# ddr32ss_EMIF_CTLCFG_0F308000h register map
Vendor: Texas Instruments
Registers are 32-bit, read-write, reset 0x0 unless marked. A register's access mark holds for its fields unless they carry their own. Offsets are as the file gives them; [hi:lo] are bit positions; {n}, {i} and the like mark numbered series.

## emif_ctlcfg (part 11 of 13)
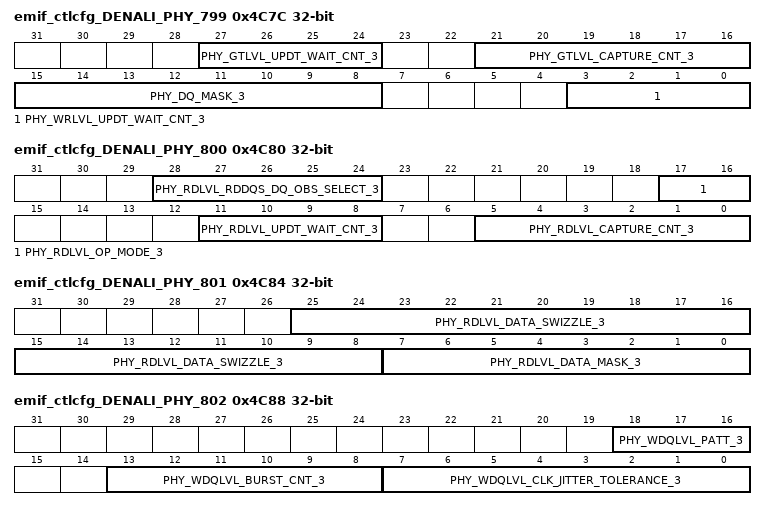
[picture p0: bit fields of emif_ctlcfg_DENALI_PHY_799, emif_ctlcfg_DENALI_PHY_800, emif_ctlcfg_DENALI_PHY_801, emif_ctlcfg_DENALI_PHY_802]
0x4C7C emif_ctlcfg_DENALI_PHY_799
  [27:24] PHY_GTLVL_UPDT_WAIT_CNT_3 — Number of cycles + 4 to wait after changing DQS target delay setting during gate training for slice 3. The valid range is 0x0 to 0xB. Reset Source: ctl_amod_g_rst_n
  [21:16] PHY_GTLVL_CAPTURE_CNT_3 — Number of samples to take at each DQS target delay setting during gate training for slice 3. Reset Source: ctl_amod_g_rst_n
  [15:8] PHY_DQ_MASK_3 — For ECC slice, should set this register to do DQ bit mask for slice 3. Reset Source: ctl_amod_g_rst_n
  [3:0] PHY_WRLVL_UPDT_WAIT_CNT_3 — Number of cycles to wait after changing DQS target delay setting during write leveling for slice 3. Reset Source: ctl_amod_g_rst_n
0x4C80 emif_ctlcfg_DENALI_PHY_800
  [28:24] PHY_RDLVL_RDDQS_DQ_OBS_SELECT_3 — Select value to map an individual DQ data window leading/trailing edge to the leading/trailing edge observation registers during read leveling for slice 3. Reset Source: ctl_amod_g_rst_n
  [17:16] PHY_RDLVL_OP_MODE_3 — Read leveling algorithm select for slice 3. Clear to 0 to move linearly from left to right. Set to 1 to start inside the window, move left and then move right. Reset Source: ctl_amod_g_rst_n
  [11:8] PHY_RDLVL_UPDT_WAIT_CNT_3 — Number of cycles to wait after changing DQS target delay setting during read leveling for slice 3. Reset Source: ctl_amod_g_rst_n
  [5:0] PHY_RDLVL_CAPTURE_CNT_3 — Number of samples to take at each DQS target delay setting during read leveling for slice 3. Reset Source: ctl_amod_g_rst_n
0x4C84 emif_ctlcfg_DENALI_PHY_801
  [25:8] PHY_RDLVL_DATA_SWIZZLE_3 — Read level bit swizzling for DDR4 operation for slice 3. Reset Source: ctl_amod_g_rst_n
  [7:0] PHY_RDLVL_DATA_MASK_3 — Per-bit mask for read leveling for slice 3. If all bits are not used, only 1 bit should be cleared to 0. Reset Source: ctl_amod_g_rst_n
0x4C88 emif_ctlcfg_DENALI_PHY_802
  [18:16] PHY_WDQLVL_PATT_3 — Defines the training patterns to be used during the write data leveling sequence for slice 3. Bit [0] corresponds to the LFSR data training pattern. Bit [1] corresponds to the CLK data training pattern. Bit [2] corresponds to user-defined data pattern training. If multiple bits are set, the training for each of the chosen patterns will be executed and the settings that give the smallest data valid window eye will be chosen. Reset Source: ctl_amod_g_rst_n
  [13:8] PHY_WDQLVL_BURST_CNT_3 — Defines the write/read burst length in bytes during the write data leveling sequence for slice 3. Reset Source: ctl_amod_g_rst_n
  [7:0] PHY_WDQLVL_CLK_JITTER_TOLERANCE_3 — Defines the minimum gap requirment for the LE and TE window for slice 3. Reset Source: ctl_amod_g_rst_n
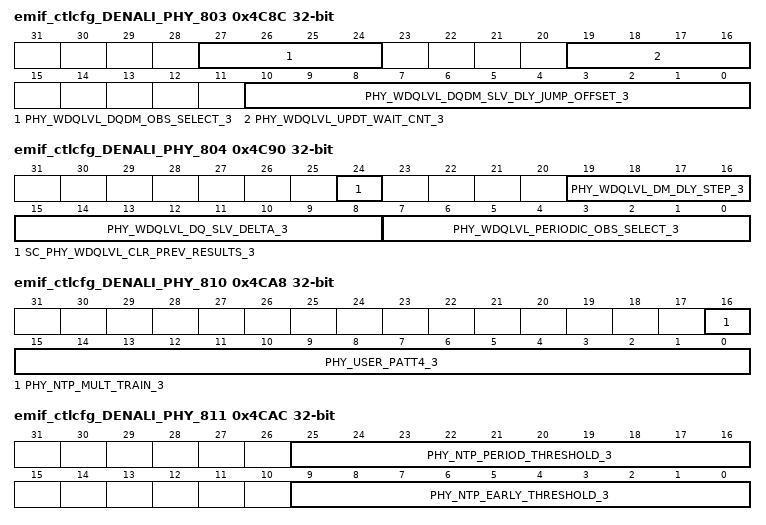
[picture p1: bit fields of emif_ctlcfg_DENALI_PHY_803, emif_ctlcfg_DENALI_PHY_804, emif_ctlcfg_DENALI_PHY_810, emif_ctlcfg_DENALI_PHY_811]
0x4C8C emif_ctlcfg_DENALI_PHY_803
  [27:24] PHY_WDQLVL_DQDM_OBS_SELECT_3 — Select value to map an individual DQ data window leading/trailing edge to the leading/trailing edge observation registers during write data leveling for slice 3. Reset Source: ctl_amod_g_rst_n
  [19:16] PHY_WDQLVL_UPDT_WAIT_CNT_3 — Number of cycles to wait after changing the DQ target delay setting during write data leveling for slice 3. Reset Source: ctl_amod_g_rst_n
  [10:0] PHY_WDQLVL_DQDM_SLV_DLY_JUMP_OFFSET_3 — Defines the target delay jump value when the TE window is found and begin to serch TE window for slice 3. Reset Source: ctl_amod_g_rst_n
0x4C90 emif_ctlcfg_DENALI_PHY_804 access per field
  [24] SC_PHY_WDQLVL_CLR_PREV_RESULTS_3 wo — Clears the previous result value to allow a clean slate comparison for future write DQ leveling results for slice 3. Set to 1 to trigger. WRITE-ONLY Reset Source: ctl_amod_g_rst_n
  [19:16] PHY_WDQLVL_DM_DLY_STEP_3 rw — The target delay line step for DM training for slice 3. Reset Source: ctl_amod_g_rst_n
  [15:8] PHY_WDQLVL_DQ_SLV_DELTA_3 rw — The margin for DQ0-7's LE and TE dealy to make sure the DQ bits can work during DM training for slice 3. Reset Source: ctl_amod_g_rst_n
  [7:0] PHY_WDQLVL_PERIODIC_OBS_SELECT_3 rw — Select value to map specific information during or post periodic write data leveling for slice 3. Reset Source: ctl_amod_g_rst_n
0x4C94 emif_ctlcfg_DENALI_PHY_805
  [8:0] PHY_WDQLVL_DATADM_MASK_3 — Per-bit mask for write data leveling for slice 3. Set to 1 to mask any bit from the leveling process. Reset Source: ctl_amod_g_rst_n
{0x4000+4i} emif_ctlcfg_DENALI_PHY_{i} (i=806..809)
  [31:0] PHY_USER_PATT{i-806}_3 — User-defined pattern to be used during write data leveling for slice 3. This register holds the bytes {4i-3221} to {4i-3224} written/read from device. Reset Source: ctl_amod_g_rst_n
0x4CA8 emif_ctlcfg_DENALI_PHY_810
  [16] PHY_NTP_MULT_TRAIN_3 — Control for single pass only No-Topology training for slice 3. Reset Source: ctl_amod_g_rst_n
  [15:0] PHY_USER_PATT4_3 — User-defined pattern to be used during write data leveling for slice 3. This register holds the DM bit for the 15 to 0 DQ written/read from device. Reset Source: ctl_amod_g_rst_n
0x4CAC emif_ctlcfg_DENALI_PHY_811
  [25:16] PHY_NTP_PERIOD_THRESHOLD_3 — Threshold Criteria of period threshold after No-Topology training is completed for slice 3. Reset Source: ctl_amod_g_rst_n
  [9:0] PHY_NTP_EARLY_THRESHOLD_3 — Threshold Criteria of early threshold after No-Topology training is completed for slice 3. Reset Source: ctl_amod_g_rst_n
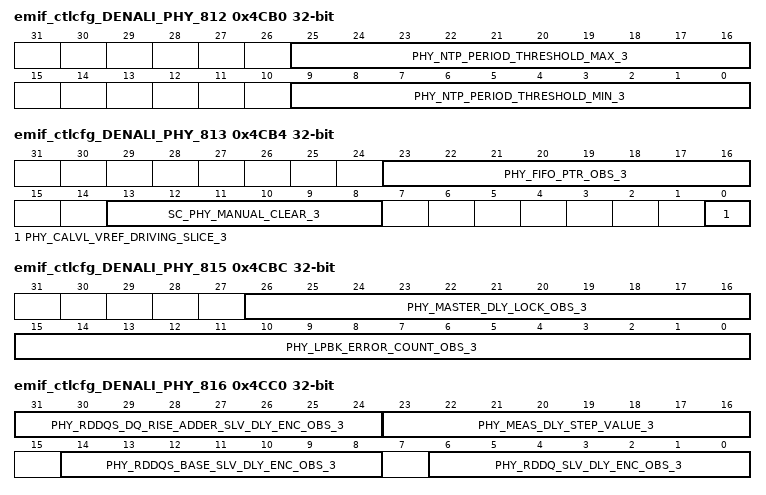
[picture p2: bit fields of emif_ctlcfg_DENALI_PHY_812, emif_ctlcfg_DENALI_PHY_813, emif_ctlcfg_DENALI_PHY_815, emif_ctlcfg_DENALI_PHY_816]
0x4CB0 emif_ctlcfg_DENALI_PHY_812
  [25:16] PHY_NTP_PERIOD_THRESHOLD_MAX_3 — Maximum Threshold that phy_clk_wrdqs_target_delay could cross boundary, to set period threshold/early threshold after No-Topology training is completed for slice 3. Reset Source: ctl_amod_g_rst_n
  [9:0] PHY_NTP_PERIOD_THRESHOLD_MIN_3 — Minimum Threshold that phy_clk_wrdqs_target_delay could cross boundary, to set period threshold/early threshold after No-Topology training is completed for slice 3. Reset Source: ctl_amod_g_rst_n
0x4CB4 emif_ctlcfg_DENALI_PHY_813 access per field
  [23:16] PHY_FIFO_PTR_OBS_3 ro — Observation register containing read entry FIFO pointers for slice 3. READ-ONLY Reset Source: ctl_amod_g_rst_n
  [13:8] SC_PHY_MANUAL_CLEAR_3 wo — Manual reset/clear of internal logic for slice 3. Bit [0] initiates manual setup of the read DQS gate. Bit [1] is reset of read entry FIFO pointers. Bit [2] is reset of master delay min/max lock values. Bit [3] is manual reset of master delay unlock counter. Bit [4] is reset of leveling error bit in the leveling status registers. Bit [5] is clearing of the gate tracking observation register. Set each bit to 1 to initiate/reset. WRITE-ONLY Reset Source: ctl_amod_g_rst_n
  [0] PHY_CALVL_VREF_DRIVING_SLICE_3 rw — Indicates if slice 3 is used to drive the VREF value to the device during CA training. Reset Source: ctl_amod_g_rst_n
0x4CB8 emif_ctlcfg_DENALI_PHY_814 ro reset 0x100000
  [31:0] PHY_LPBK_RESULT_OBS_3 — Observation register containing loopback status/results for slice 3. READ-ONLY Reset Source: ctl_amod_g_rst_n
0x4CBC emif_ctlcfg_DENALI_PHY_815 ro
  [26:16] PHY_MASTER_DLY_LOCK_OBS_3 — Observation register containing master delay results for slice 3. READ-ONLY Reset Source: ctl_amod_g_rst_n
  [15:0] PHY_LPBK_ERROR_COUNT_OBS_3 — Observation register containing total number of loopback error data for slice 3. READ-ONLY Reset Source: ctl_amod_g_rst_n
0x4CC0 emif_ctlcfg_DENALI_PHY_816 ro
  [31:24] PHY_RDDQS_DQ_RISE_ADDER_SLV_DLY_ENC_OBS_3 — Observation register containing read DQS DQ rising edge adder target delay encoded value for slice 3. READ-ONLY Reset Source: ctl_amod_g_rst_n
  [23:16] PHY_MEAS_DLY_STEP_VALUE_3 — Observation register containing fraction of the cycle in 1 delay element, numerator with demominator of 512, for slice 3. READ-ONLY Reset Source: ctl_amod_g_rst_n
  [14:8] PHY_RDDQS_BASE_SLV_DLY_ENC_OBS_3 — Observation register containing read DQS base target delay encoded value for slice 3. READ-ONLY Reset Source: ctl_amod_g_rst_n
  [6:0] PHY_RDDQ_SLV_DLY_ENC_OBS_3 — Observation register containing read DQ target delay encoded values for slice 3. READ-ONLY Reset Source: ctl_amod_g_rst_n
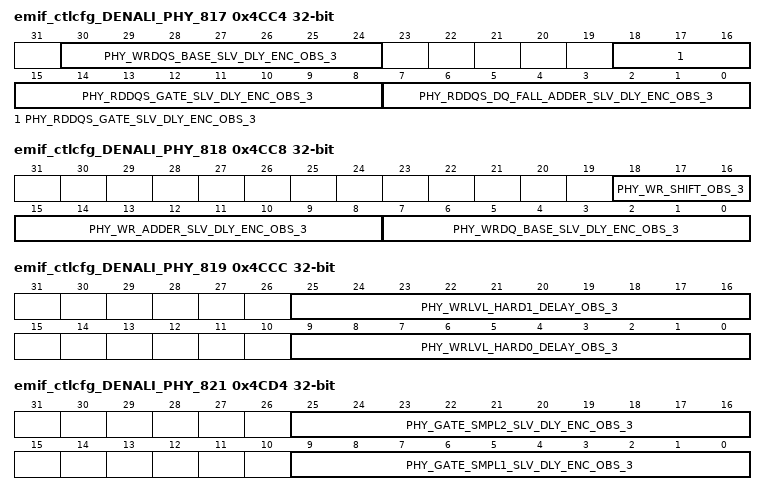
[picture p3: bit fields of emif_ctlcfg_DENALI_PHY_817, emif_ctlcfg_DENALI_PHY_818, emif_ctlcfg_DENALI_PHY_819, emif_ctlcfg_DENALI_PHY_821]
0x4CC4 emif_ctlcfg_DENALI_PHY_817 ro
  [30:24] PHY_WRDQS_BASE_SLV_DLY_ENC_OBS_3 — Observation register containing write DQS base target delay encoded value for slice 3. READ-ONLY Reset Source: ctl_amod_g_rst_n
  [18:8] PHY_RDDQS_GATE_SLV_DLY_ENC_OBS_3 — Observation register containing read DQS gate target delay encoded value for slice 3. READ-ONLY Reset Source: ctl_amod_g_rst_n
  [7:0] PHY_RDDQS_DQ_FALL_ADDER_SLV_DLY_ENC_OBS_3 — Observation register containing read DQS DQ falling edge adder target delay encoded value for slice 3. READ-ONLY Reset Source: ctl_amod_g_rst_n
0x4CC8 emif_ctlcfg_DENALI_PHY_818 ro
  [18:16] PHY_WR_SHIFT_OBS_3 — Observation register containing automatic half cycle and cycle shift values for slice 3. READ-ONLY Reset Source: ctl_amod_g_rst_n
  [15:8] PHY_WR_ADDER_SLV_DLY_ENC_OBS_3 — Observation register containing write adder target delay encoded value for slice 3. READ-ONLY Reset Source: ctl_amod_g_rst_n
  [7:0] PHY_WRDQ_BASE_SLV_DLY_ENC_OBS_3 — Observation register containing write DQ base target delay encoded value for slice 3. READ-ONLY Reset Source: ctl_amod_g_rst_n
0x4CCC emif_ctlcfg_DENALI_PHY_819 ro
  [25:16] PHY_WRLVL_HARD1_DELAY_OBS_3 — Observation register containing write leveling first hard 1 DQS target delay for slice 3. READ-ONLY Reset Source: ctl_amod_g_rst_n
  [9:0] PHY_WRLVL_HARD0_DELAY_OBS_3 — Observation register containing write leveling last hard 0 DQS target delay for slice 3. READ-ONLY Reset Source: ctl_amod_g_rst_n
0x4CD0 emif_ctlcfg_DENALI_PHY_820 ro
  [20:0] PHY_WRLVL_STATUS_OBS_3 — Observation register containing write leveling status for slice 3. READ-ONLY Reset Source: ctl_amod_g_rst_n
0x4CD4 emif_ctlcfg_DENALI_PHY_821 ro
  [25:16] PHY_GATE_SMPL2_SLV_DLY_ENC_OBS_3 — Observation register containing gate sample2 target delay encoded values for slice 3. READ-ONLY Reset Source: ctl_amod_g_rst_n
  [9:0] PHY_GATE_SMPL1_SLV_DLY_ENC_OBS_3 — Observation register containing gate sample1 target delay encoded values for slice 3. READ-ONLY Reset Source: ctl_amod_g_rst_n
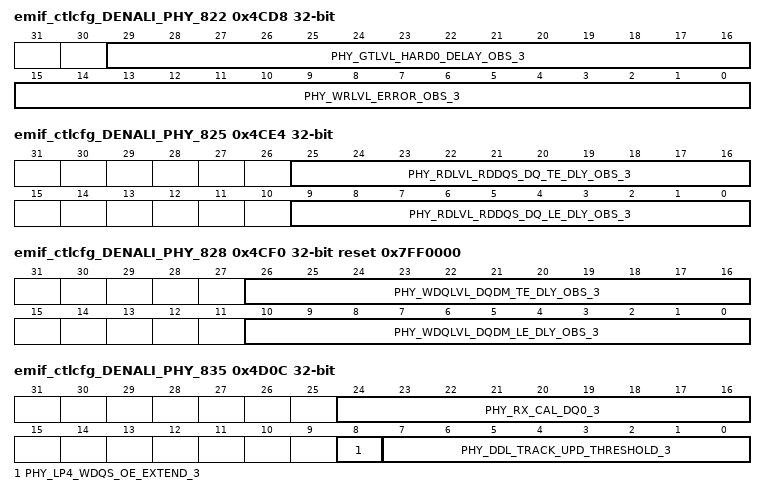
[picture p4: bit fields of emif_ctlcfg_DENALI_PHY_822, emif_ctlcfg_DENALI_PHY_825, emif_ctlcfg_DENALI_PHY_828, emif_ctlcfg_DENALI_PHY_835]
0x4CD8 emif_ctlcfg_DENALI_PHY_822 ro
  [29:16] PHY_GTLVL_HARD0_DELAY_OBS_3 — Observation register containing gate training first hard 0 DQS target delay for slice 3. READ-ONLY Reset Source: ctl_amod_g_rst_n
  [15:0] PHY_WRLVL_ERROR_OBS_3 — Observation register containing write leveling error status for slice 3. READ-ONLY Reset Source: ctl_amod_g_rst_n
0x4CDC emif_ctlcfg_DENALI_PHY_823 ro
  [13:0] PHY_GTLVL_HARD1_DELAY_OBS_3 — Observation register containing gate training last hard 1 DQS target delay for slice 3. READ-ONLY Reset Source: ctl_amod_g_rst_n
0x4CE0 emif_ctlcfg_DENALI_PHY_824 ro
  [17:0] PHY_GTLVL_STATUS_OBS_3 — Observation register containing gate training status for slice 3. READ-ONLY Reset Source: ctl_amod_g_rst_n
0x4CE4 emif_ctlcfg_DENALI_PHY_825 ro
  [25:16] PHY_RDLVL_RDDQS_DQ_TE_DLY_OBS_3 — Observation register containing read leveling data window trailing edge target delay setting for slice 3. READ-ONLY Reset Source: ctl_amod_g_rst_n
  [9:0] PHY_RDLVL_RDDQS_DQ_LE_DLY_OBS_3 — Observation register containing read leveling data window leading edge target delay setting for slice 3. READ-ONLY Reset Source: ctl_amod_g_rst_n
0x4CE8 emif_ctlcfg_DENALI_PHY_826 ro
  [1:0] PHY_RDLVL_RDDQS_DQ_NUM_WINDOWS_OBS_3 — Observation register containing read leveling number of windows found for slice 3. READ-ONLY Reset Source: ctl_amod_g_rst_n
0x4CEC emif_ctlcfg_DENALI_PHY_827 ro
  [31:0] PHY_RDLVL_STATUS_OBS_3 — Observation register containing read leveling status for slice 3. READ-ONLY Reset Source: ctl_amod_g_rst_n
0x4CF0 emif_ctlcfg_DENALI_PHY_828 ro reset 0x7FF0000
  [26:16] PHY_WDQLVL_DQDM_TE_DLY_OBS_3 — Observation register containing write data leveling data window trailing edge target delay setting for slice 3. READ-ONLY Reset Source: ctl_amod_g_rst_n
  [10:0] PHY_WDQLVL_DQDM_LE_DLY_OBS_3 — Observation register containing write data leveling data window leading edge target delay setting for slice 3. READ-ONLY Reset Source: ctl_amod_g_rst_n
0x4CF4 emif_ctlcfg_DENALI_PHY_829 ro
  [31:0] PHY_WDQLVL_STATUS_OBS_3 — Observation register containing write data leveling status for slice 3. READ-ONLY Reset Source: ctl_amod_g_rst_n
0x4CF8 emif_ctlcfg_DENALI_PHY_830 ro
  [31:0] PHY_WDQLVL_PERIODIC_OBS_3 — Observation register containing periodic write data leveling status for slice 3. READ-ONLY Reset Source: ctl_amod_g_rst_n
0x4CFC emif_ctlcfg_DENALI_PHY_831
  [30:0] PHY_DDL_MODE_3 — DDL mode for slice 3. Reset Source: ctl_amod_g_rst_n
0x4D00 emif_ctlcfg_DENALI_PHY_832
  [5:0] PHY_DDL_MASK_3 — DDL mask for slice 3. Reset Source: ctl_amod_g_rst_n
0x4D04 emif_ctlcfg_DENALI_PHY_833 ro
  [31:0] PHY_DDL_TEST_OBS_3 — DDL test observation for slice 3. READ-ONLY Reset Source: ctl_amod_g_rst_n
0x4D08 emif_ctlcfg_DENALI_PHY_834 ro
  [31:0] PHY_DDL_TEST_MSTR_DLY_OBS_3 — DDL test observation delays for slice 3 master DDL. READ-ONLY Reset Source: ctl_amod_g_rst_n
0x4D0C emif_ctlcfg_DENALI_PHY_835
  [24:16] PHY_RX_CAL_DQ0_3 — RX Calibration codes for DQ0 for slice 3. Bits [5:0] contain rx_cal_code_down. Bits [11:6] contain rx_cal_code_up. Bits [17:12] contain rx_cal_code2_down. Bits [23:18] contain rx_cal_code2_up. Reset Source: ctl_amod_g_rst_n
  [8] PHY_LP4_WDQS_OE_EXTEND_3 — LPDDR4 write preamble extension enable for slice 3. Reset Source: ctl_amod_g_rst_n
  [7:0] PHY_DDL_TRACK_UPD_THRESHOLD_3 — Specify threshold value for PHY init update tracking for slice 3. Reset Source: ctl_amod_g_rst_n
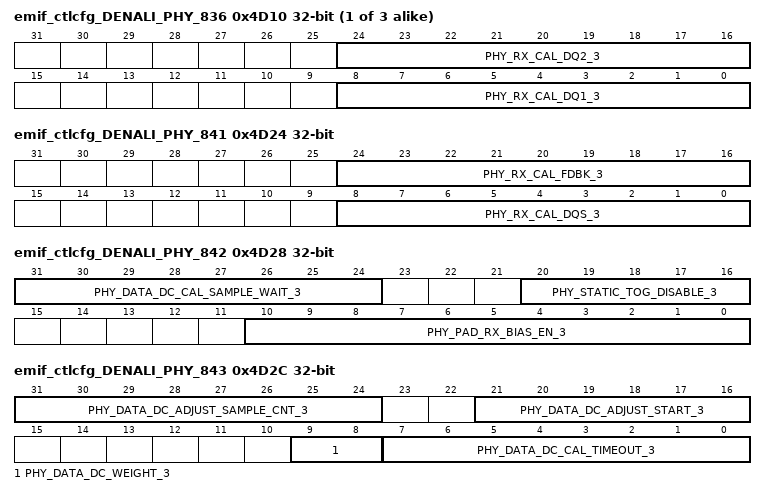
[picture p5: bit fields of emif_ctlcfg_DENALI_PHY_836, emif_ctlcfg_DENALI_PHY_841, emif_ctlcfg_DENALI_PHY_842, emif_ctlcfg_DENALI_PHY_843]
{0x4000+4i} emif_ctlcfg_DENALI_PHY_{i} (i=836..838)
  [24:16] PHY_RX_CAL_DQ{2i-1670}_3 — RX Calibration codes for DQ{2i-1670} for slice 3. Bits [5:0] contain rx_cal_code_down. Bits [11:6] contain rx_cal_code_up. Bits [17:12] contain rx_cal_code2_down. Bits [23:18] contain rx_cal_code2_up. Reset Source: ctl_amod_g_rst_n
  [8:0] PHY_RX_CAL_DQ{2i-1671}_3 — RX Calibration codes for DQ{2i-1671} for slice 3. Bits [5:0] contain rx_cal_code_down. Bits [11:6] contain rx_cal_code_up. Bits [17:12] contain rx_cal_code2_down. Bits [23:18] contain rx_cal_code2_up. Reset Source: ctl_amod_g_rst_n
0x4D1C emif_ctlcfg_DENALI_PHY_839
  [8:0] PHY_RX_CAL_DQ7_3 — RX Calibration codes for DQ7 for slice 3. Bits [5:0] contain rx_cal_code_down. Bits [11:6] contain rx_cal_code_up. Bits [17:12] contain rx_cal_code2_down. Bits [23:18] contain rx_cal_code2_up. Reset Source: ctl_amod_g_rst_n
0x4D20 emif_ctlcfg_DENALI_PHY_840
  [17:0] PHY_RX_CAL_DM_3 — RX Calibration codes for DM for slice 3. Bits [5:0] contain rx_cal_code_down. Bits [11:6] contain rx_cal_code_up. Bits [17:12] contain rx_cal_code2_down. Bits [23:18] contain rx_cal_code2_up. Reset Source: ctl_amod_g_rst_n
0x4D24 emif_ctlcfg_DENALI_PHY_841
  [24:16] PHY_RX_CAL_FDBK_3 — RX Calibration codes for FDBK for slice 3. Bits [5:0] contain rx_cal_code_down. Bits [11:6] contain rx_cal_code_up. Bits [17:12] contain rx_cal_code2_down. Bits [23:18] contain rx_cal_code2_up. Reset Source: ctl_amod_g_rst_n
  [8:0] PHY_RX_CAL_DQS_3 — RX Calibration codes for DQS for slice 3. Bits [5:0] contain rx_cal_code_down. Bits [11:6] contain rx_cal_code_up. Bits [17:12] contain rx_cal_code2_down. Bits [23:18] contain rx_cal_code2_up. Reset Source: ctl_amod_g_rst_n
0x4D28 emif_ctlcfg_DENALI_PHY_842
  [31:24] PHY_DATA_DC_CAL_SAMPLE_WAIT_3 — Determines number of cycles to wait for each sample for slice 3. Reset Source: ctl_amod_g_rst_n
  [20:16] PHY_STATIC_TOG_DISABLE_3 — Control to disable toggle during static activity for slice 3. bit0: Write path delay line disable; bit1: Read path delay line disable; bit2: Read data path disable; bit3: clk_phy disable; bit4: master delay line disable. Reset Source: ctl_amod_g_rst_n
  [10:0] PHY_PAD_RX_BIAS_EN_3 — Controls RX_BIAS_EN pin for each pad for slice 3. Reset Source: ctl_amod_g_rst_n
0x4D2C emif_ctlcfg_DENALI_PHY_843
  [31:24] PHY_DATA_DC_ADJUST_SAMPLE_CNT_3 — Duty cycle adjust sample count for slice 3. Reset Source: ctl_amod_g_rst_n
  [21:16] PHY_DATA_DC_ADJUST_START_3 — Duty cycle adjust starting value for slice 3. Reset Source: ctl_amod_g_rst_n
  [9:8] PHY_DATA_DC_WEIGHT_3 — Determines weight of average calculating for slice 3. Reset Source: ctl_amod_g_rst_n
  [7:0] PHY_DATA_DC_CAL_TIMEOUT_3 — Determines timeout number of iteration for slice 3. Reset Source: ctl_amod_g_rst_n
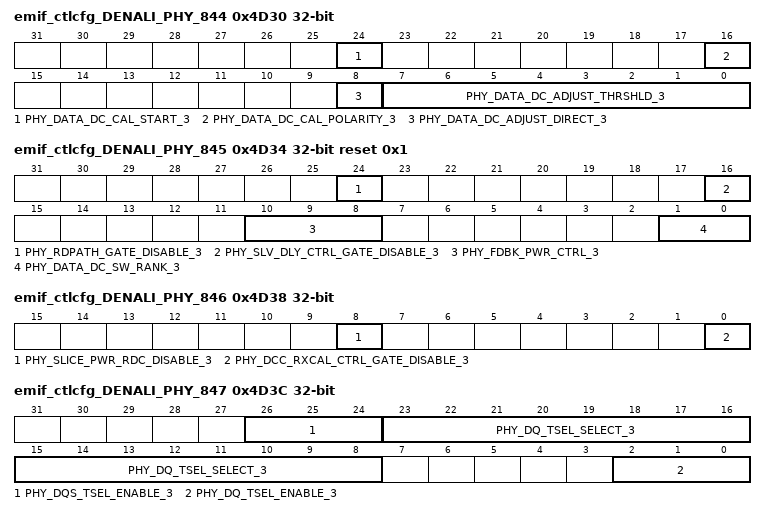
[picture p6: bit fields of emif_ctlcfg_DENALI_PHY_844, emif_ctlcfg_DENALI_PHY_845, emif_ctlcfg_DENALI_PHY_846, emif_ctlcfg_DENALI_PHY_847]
0x4D30 emif_ctlcfg_DENALI_PHY_844
  [24] PHY_DATA_DC_CAL_START_3 — Manual trigger for DCC for slice 3. Reset Source: ctl_amod_g_rst_n
  [16] PHY_DATA_DC_CAL_POLARITY_3 — Calibration polarity for slice 3. Reset Source: ctl_amod_g_rst_n
  [8] PHY_DATA_DC_ADJUST_DIRECT_3 — Adjust direction for slice 3. Reset Source: ctl_amod_g_rst_n
  [7:0] PHY_DATA_DC_ADJUST_THRSHLD_3 — Duty cycle adjust threshold around the mid-point for slice 3. Reset Source: ctl_amod_g_rst_n
0x4D34 emif_ctlcfg_DENALI_PHY_845 reset 0x1
  [24] PHY_RDPATH_GATE_DISABLE_3 — Data slice read path power reduction disable for slice 3. Reset Source: ctl_amod_g_rst_n
  [16] PHY_SLV_DLY_CTRL_GATE_DISABLE_3 — Data slice slv_dly_control block power reduction disable for slice 3. Reset Source: ctl_amod_g_rst_n
  [10:8] PHY_FDBK_PWR_CTRL_3 — Shutoff gate feedback IO to reduce power for slice 3. Reset Source: ctl_amod_g_rst_n
  [1:0] PHY_DATA_DC_SW_RANK_3 — Rank selection for software based duty cycle correction for slice 3. Reset Source: ctl_amod_g_rst_n
0x4D38 emif_ctlcfg_DENALI_PHY_846
  [8] PHY_SLICE_PWR_RDC_DISABLE_3 — Data slice power reduction disable for slice 3. Reset Source: ctl_amod_g_rst_n
  [0] PHY_DCC_RXCAL_CTRL_GATE_DISABLE_3 — Data slice DCC and RX_CAL block power reduction disable for slice 3. Reset Source: ctl_amod_g_rst_n
0x4D3C emif_ctlcfg_DENALI_PHY_847
  [26:24] PHY_DQS_TSEL_ENABLE_3 — Operation type tsel enables for DQS signals for slice 3. Bit [0] enables tsel_en during read cycles. Bit [1] enables tsel_en during write cycles. Bit [2] enables tsel_en during idle cycles. Set each bit to 1 to enable. Reset Source: ctl_amod_g_rst_n
  [23:8] PHY_DQ_TSEL_SELECT_3 — Operation type tsel select values for DQ/DM signals for slice 3. Reset Source: ctl_amod_g_rst_n
  [2:0] PHY_DQ_TSEL_ENABLE_3 — Operation type tsel enables for DQ/DM signals for slice 3. Bit [0] enables tsel_en during read cycles. Bit [1] enables tsel_en during write cycles. Bit [2] enables tsel_en during idle cycles. Set each bit to 1 to enable. Reset Source: ctl_amod_g_rst_n
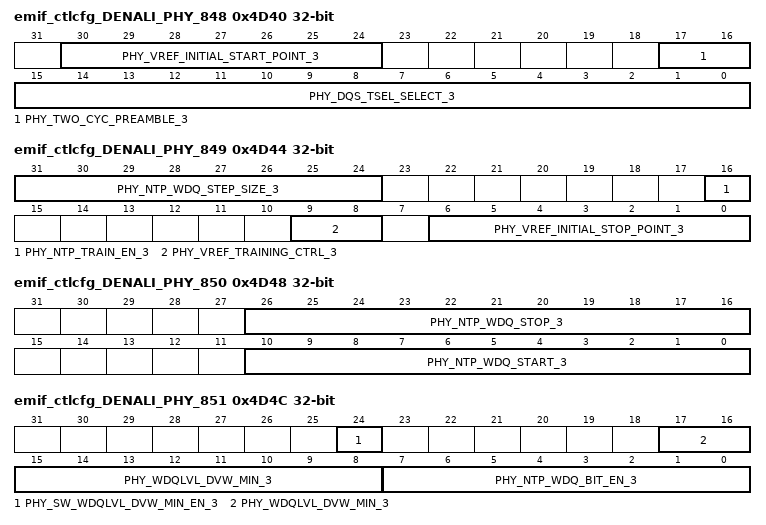
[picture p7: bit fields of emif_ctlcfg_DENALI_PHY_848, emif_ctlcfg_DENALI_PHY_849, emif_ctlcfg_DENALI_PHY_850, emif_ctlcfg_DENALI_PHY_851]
0x4D40 emif_ctlcfg_DENALI_PHY_848
  [30:24] PHY_VREF_INITIAL_START_POINT_3 — Data slice initial VREF training start value for slice 3. Reset Source: ctl_amod_g_rst_n
  [17:16] PHY_TWO_CYC_PREAMBLE_3 — 2 cycle preamble support for slice 3. Bit [0] controls the 2 cycle read preamble. Bit [1] controls the 2 cycle write preamble. Set each bit to 1 to enable. Reset Source: ctl_amod_g_rst_n
  [15:0] PHY_DQS_TSEL_SELECT_3 — Operation type tsel select values for DQS signals for slice 3. Reset Source: ctl_amod_g_rst_n
0x4D44 emif_ctlcfg_DENALI_PHY_849
  [31:24] PHY_NTP_WDQ_STEP_SIZE_3 — Step size of WR DQ target delay during No-Topology training for slice 3. Reset Source: ctl_amod_g_rst_n
  [16] PHY_NTP_TRAIN_EN_3 — Enable for No-Topology training for slice 3. Reset Source: ctl_amod_g_rst_n
  [9:8] PHY_VREF_TRAINING_CTRL_3 — Data slice vref training enable control for slice 3. Reset Source: ctl_amod_g_rst_n
  [6:0] PHY_VREF_INITIAL_STOP_POINT_3 — Data slice initial VREF training stop value for slice 3. Reset Source: ctl_amod_g_rst_n
0x4D48 emif_ctlcfg_DENALI_PHY_850
  [26:16] PHY_NTP_WDQ_STOP_3 — End of WR DQ target delay in No-Topology training for slice 3. Reset Source: ctl_amod_g_rst_n
  [10:0] PHY_NTP_WDQ_START_3 — Starting WR DQ target delay in No-Topology training for slice 3. Reset Source: ctl_amod_g_rst_n
0x4D4C emif_ctlcfg_DENALI_PHY_851
  [24] PHY_SW_WDQLVL_DVW_MIN_EN_3 — SW override to enable use of PHY_WDQLVL_DVW_MIN for slice 3. Reset Source: ctl_amod_g_rst_n
  [17:8] PHY_WDQLVL_DVW_MIN_3 — Minimum data valid window across DQs and ranks for slice 3. Reset Source: ctl_amod_g_rst_n
  [7:0] PHY_NTP_WDQ_BIT_EN_3 — Enable Bit for WR DQ during No-Topology training for slice 3. Reset Source: ctl_amod_g_rst_n
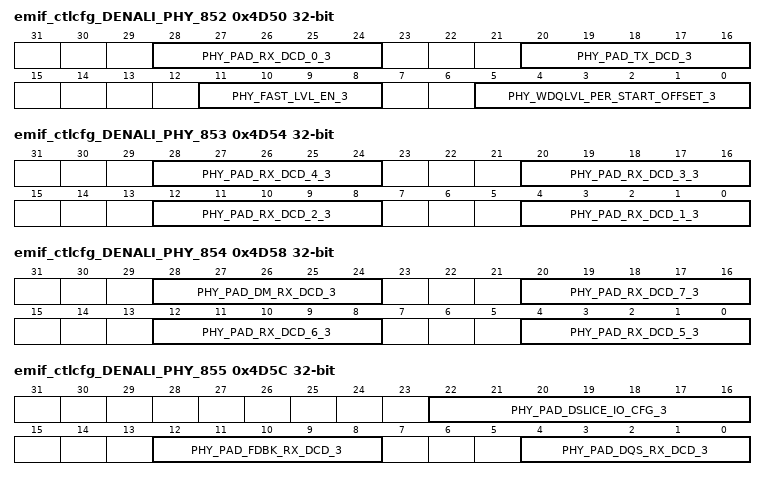
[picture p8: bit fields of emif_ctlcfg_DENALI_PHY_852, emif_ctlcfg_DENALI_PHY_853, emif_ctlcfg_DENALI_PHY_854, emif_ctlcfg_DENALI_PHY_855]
0x4D50 emif_ctlcfg_DENALI_PHY_852
  [28:24] PHY_PAD_RX_DCD_0_3 — Controls RX_DCD pin for each pad for slice 3. Reset Source: ctl_amod_g_rst_n
  [20:16] PHY_PAD_TX_DCD_3 — Controls TX_DCD pin for each pad for slice 3. Reset Source: ctl_amod_g_rst_n
  [11:8] PHY_FAST_LVL_EN_3 — Enable for fast multi-pattern window search for slice 3. Reset Source: ctl_amod_g_rst_n
  [5:0] PHY_WDQLVL_PER_START_OFFSET_3 — Peridic training start point offset for slice 3. Reset Source: ctl_amod_g_rst_n
0x4D54 emif_ctlcfg_DENALI_PHY_853
  [8n-4:8n-8] PHY_PAD_RX_DCD_{n}_3 (n=1..4) — Controls RX_DCD pin for each pad for slice 3. Reset Source: ctl_amod_g_rst_n
0x4D58 emif_ctlcfg_DENALI_PHY_854
  [28:24] PHY_PAD_DM_RX_DCD_3 — Controls RX_DCD pin for dm pad for slice 3. Reset Source: ctl_amod_g_rst_n
  [20:16] PHY_PAD_RX_DCD_7_3 — Controls RX_DCD pin for each pad for slice 3. Reset Source: ctl_amod_g_rst_n
  [12:8] PHY_PAD_RX_DCD_6_3 — Controls RX_DCD pin for each pad for slice 3. Reset Source: ctl_amod_g_rst_n
  [4:0] PHY_PAD_RX_DCD_5_3 — Controls RX_DCD pin for each pad for slice 3. Reset Source: ctl_amod_g_rst_n
0x4D5C emif_ctlcfg_DENALI_PHY_855
  [22:16] PHY_PAD_DSLICE_IO_CFG_3 — Controls PCLK/PARK pin for pad for slice 3. Reset Source: ctl_amod_g_rst_n
  [12:8] PHY_PAD_FDBK_RX_DCD_3 — Controls RX_DCD pin for fdbk pad for slice 3. Reset Source: ctl_amod_g_rst_n
  [4:0] PHY_PAD_DQS_RX_DCD_3 — Controls RX_DCD pin for dqs pad for slice 3. Reset Source: ctl_amod_g_rst_n
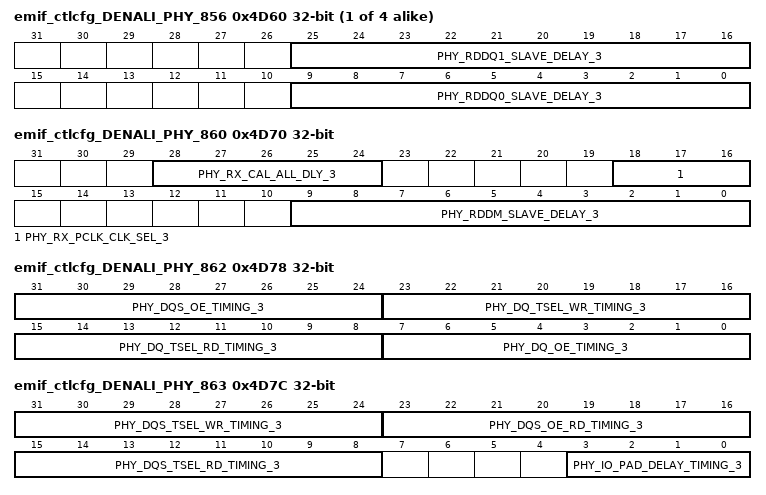
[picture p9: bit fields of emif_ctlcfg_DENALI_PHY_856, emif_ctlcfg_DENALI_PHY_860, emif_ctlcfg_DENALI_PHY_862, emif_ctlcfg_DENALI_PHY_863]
{0x4000+4i} emif_ctlcfg_DENALI_PHY_{i} (i=856..859)
  [25:16] PHY_RDDQ{2i-1711}_SLAVE_DELAY_3 — Read DQ{2i-1711} target delay setting for slice 3. Reset Source: ctl_amod_g_rst_n
  [9:0] PHY_RDDQ{2i-1712}_SLAVE_DELAY_3 — Read DQ{2i-1712} target delay setting for slice 3. Reset Source: ctl_amod_g_rst_n
0x4D70 emif_ctlcfg_DENALI_PHY_860
  [28:24] PHY_RX_CAL_ALL_DLY_3 — Defines the number of cycles/half cycles that the rx_cal_all_opad signal should be asserted for. There is a phy_rx_cal_all_dly_X parameter for each of the slices of data sent on the DFI data bus for slice 3. Reset Source: ctl_amod_g_rst_n
  [18:16] PHY_RX_PCLK_CLK_SEL_3 — RX_PCLK clock frequency selection for slice 3. Reset Source: ctl_amod_g_rst_n
  [9:0] PHY_RDDM_SLAVE_DELAY_3 — Read DM/DBI target delay setting for slice 3. May be used for data swap. Reset Source: ctl_amod_g_rst_n
0x4D74 emif_ctlcfg_DENALI_PHY_861
  [2:0] PHY_DATA_DC_CAL_CLK_SEL_3 — Determines DCC CAL clock for slice 3. Reset Source: ctl_amod_g_rst_n
0x4D78 emif_ctlcfg_DENALI_PHY_862
  [31:24] PHY_DQS_OE_TIMING_3 — Start/end timing values for DQS output enable signals for slice 3. Reset Source: ctl_amod_g_rst_n
  [23:16] PHY_DQ_TSEL_WR_TIMING_3 — Start/end timing values for DQ/DM write based termination enable and select signals for slice 3. Reset Source: ctl_amod_g_rst_n
  [15:8] PHY_DQ_TSEL_RD_TIMING_3 — Start/end timing values for DQ/DM read based termination enable and select signals for slice 3. Reset Source: ctl_amod_g_rst_n
  [7:0] PHY_DQ_OE_TIMING_3 — Start/end timing values for DQ/DM output enable signals for slice 3. Reset Source: ctl_amod_g_rst_n
0x4D7C emif_ctlcfg_DENALI_PHY_863
  [31:24] PHY_DQS_TSEL_WR_TIMING_3 — Start/end timing values for DQS write based termination enable and select signals for slice 3. Reset Source: ctl_amod_g_rst_n
  [23:16] PHY_DQS_OE_RD_TIMING_3 — Start/end timing values for DQS read based OE extension for slice 3. Reset Source: ctl_amod_g_rst_n
  [15:8] PHY_DQS_TSEL_RD_TIMING_3 — Start/end timing values for DQS read based termination enable and select signals for slice 3. Reset Source: ctl_amod_g_rst_n
  [3:0] PHY_IO_PAD_DELAY_TIMING_3 — Feedback pad's OPAD and IPAD delay timing for slice 3. Reset Source: ctl_amod_g_rst_n
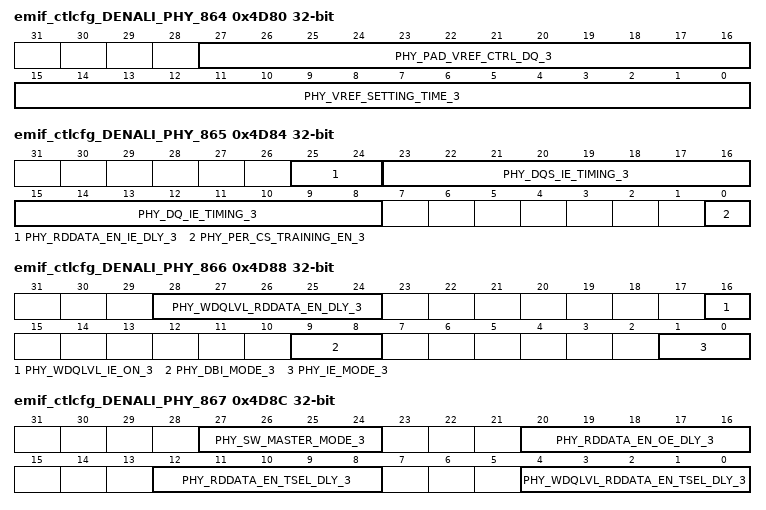
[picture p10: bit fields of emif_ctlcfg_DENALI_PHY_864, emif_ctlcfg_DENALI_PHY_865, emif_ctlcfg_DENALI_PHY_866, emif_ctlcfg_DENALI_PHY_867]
0x4D80 emif_ctlcfg_DENALI_PHY_864
  [27:16] PHY_PAD_VREF_CTRL_DQ_3 — Pad VREF control settings for DQ slice 3. Reset Source: ctl_amod_g_rst_n
  [15:0] PHY_VREF_SETTING_TIME_3 — Number of cycles for vref settle after setting is changed for slice 3. Reset Source: ctl_amod_g_rst_n
0x4D84 emif_ctlcfg_DENALI_PHY_865
  [25:24] PHY_RDDATA_EN_IE_DLY_3 — Number of cycles that the dfi_rddata_en signal is earlier than necessary for input enable generation for slice 3. Reset Source: ctl_amod_g_rst_n
  [23:16] PHY_DQS_IE_TIMING_3 — Start/end timing values for DQS input enable signals for slice 3. Reset Source: ctl_amod_g_rst_n
  [15:8] PHY_DQ_IE_TIMING_3 — Start/end timing values for DQ/DM input enable signals for slice 3. Reset Source: ctl_amod_g_rst_n
  [0] PHY_PER_CS_TRAINING_EN_3 — Enables the per-rank training and read/write timing capabilities for slice 3. Must have same value in all slices. Reset Source: ctl_amod_g_rst_n
0x4D88 emif_ctlcfg_DENALI_PHY_866
  [28:24] PHY_WDQLVL_RDDATA_EN_DLY_3 — For WR DQ training, the number of cycles that the dfi_rddata_en signal is early for slice 3. Reset Source: ctl_amod_g_rst_n
  [16] PHY_WDQLVL_IE_ON_3 — IE control, 1 meams IE is always on during WR DQ training for slice 3. Reset Source: ctl_amod_g_rst_n
  [9:8] PHY_DBI_MODE_3 — DBI mode for slice 3. Bit [0] enables return of DBI read data. Reset Source: ctl_amod_g_rst_n
  [1:0] PHY_IE_MODE_3 — Input enable mode bits for slice 3. Bit [0] enables the mode where the input enables are always on; set to 1 to enable. Bit [1] disables the input enable on the DM signal; set to 1 to disable. Reset Source: ctl_amod_g_rst_n
0x4D8C emif_ctlcfg_DENALI_PHY_867
  [27:24] PHY_SW_MASTER_MODE_3 — Master delay line override settings for slice 3. Bit [0] enables software half clock mode. Bit [1] is the software half clock mode value. Bit [2] enables software bypass mode. Bit [3] is the software bypass mode value. Reset Source: ctl_amod_g_rst_n
  [20:16] PHY_RDDATA_EN_OE_DLY_3 — Number of cycles that the dfi_rddata_en signal is earlier than necessary for LP4 OE extension generation for slice 3. Reset Source: ctl_amod_g_rst_n
  [12:8] PHY_RDDATA_EN_TSEL_DLY_3 — Number of cycles that the dfi_rddata_en signal is earlier than necessary for TSEL enable generation for slice 3. Reset Source: ctl_amod_g_rst_n
  [4:0] PHY_WDQLVL_RDDATA_EN_TSEL_DLY_3 — For WR DQ training, the number of cycles that the dfi_rddata_en signal is earlier than necessary for TSEL enable generation for slice 3. Reset Source: ctl_amod_g_rst_n
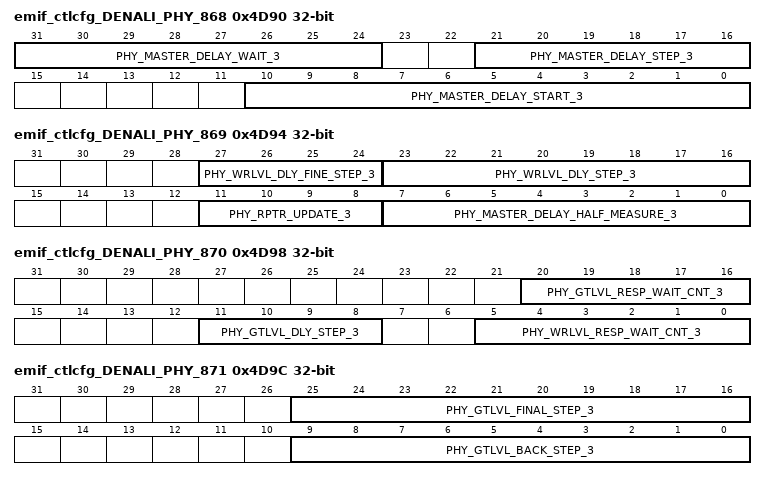
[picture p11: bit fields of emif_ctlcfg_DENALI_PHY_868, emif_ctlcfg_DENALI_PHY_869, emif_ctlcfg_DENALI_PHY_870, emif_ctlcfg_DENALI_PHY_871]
0x4D90 emif_ctlcfg_DENALI_PHY_868
  [31:24] PHY_MASTER_DELAY_WAIT_3 — Wait cycles for master delay line locking algorithm for slice 3. Bits [3:0] are the cycle wait count after a calibration clock setting change. Bits [7:4] are the cycle wait count after a master delay setting change. Reset Source: ctl_amod_g_rst_n
  [21:16] PHY_MASTER_DELAY_STEP_3 — Incremental step size for master delay line locking algorithm for slice 3. Reset Source: ctl_amod_g_rst_n
  [10:0] PHY_MASTER_DELAY_START_3 — Start value for master delay line locking algorithm for slice 3. Reset Source: ctl_amod_g_rst_n
0x4D94 emif_ctlcfg_DENALI_PHY_869
  [27:24] PHY_WRLVL_DLY_FINE_STEP_3 — DQS target delay fine step size during write leveling for slice 3. Reset Source: ctl_amod_g_rst_n
  [23:16] PHY_WRLVL_DLY_STEP_3 — DQS target delay step size during write leveling for slice 3. Reset Source: ctl_amod_g_rst_n
  [11:8] PHY_RPTR_UPDATE_3 — Offset in cycles from the dfi_rddata_en signal to release data from the entry FIFO for slice 3. Reset Source: ctl_amod_g_rst_n
  [7:0] PHY_MASTER_DELAY_HALF_MEASURE_3 — Defines the number of delay line elements to be considered in determing whether to lock to a half clock cycle in the data slice master for slice 3. Reset Source: ctl_amod_g_rst_n
0x4D98 emif_ctlcfg_DENALI_PHY_870
  [20:16] PHY_GTLVL_RESP_WAIT_CNT_3 — Number of cycles + 4 to wait between dfi_rddata_en and the sampling of the DQS during gate training for slice 3. The valid range is 0x0 to 0xB. Reset Source: ctl_amod_g_rst_n
  [11:8] PHY_GTLVL_DLY_STEP_3 — DQS target delay step size during gate training for slice 3. Reset Source: ctl_amod_g_rst_n
  [5:0] PHY_WRLVL_RESP_WAIT_CNT_3 — Number of cycles to wait between dfi_wrlvl_strobe and the sampling of the DQs during write leveling for slice 3. Reset Source: ctl_amod_g_rst_n
0x4D9C emif_ctlcfg_DENALI_PHY_871
  [25:16] PHY_GTLVL_FINAL_STEP_3 — Final backup step delay used in gate training algorithm for slice 3. Reset Source: ctl_amod_g_rst_n
  [9:0] PHY_GTLVL_BACK_STEP_3 — Interim backup step delay used in gate training algorithm for slice 3. Reset Source: ctl_amod_g_rst_n
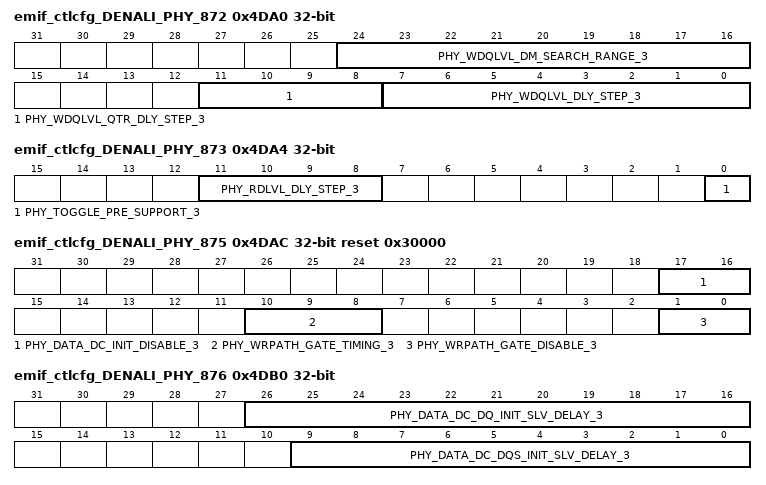
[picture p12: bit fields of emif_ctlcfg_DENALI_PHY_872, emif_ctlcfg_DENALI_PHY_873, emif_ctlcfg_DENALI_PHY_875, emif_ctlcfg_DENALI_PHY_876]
0x4DA0 emif_ctlcfg_DENALI_PHY_872
  [24:16] PHY_WDQLVL_DM_SEARCH_RANGE_3 — The dm target delay search range for non-lpddr4 DM training for slice 3. Reset Source: ctl_amod_g_rst_n
  [11:8] PHY_WDQLVL_QTR_DLY_STEP_3 — Defines the step granularity for the logic to use once an edge is found for slice 3. When this occurs, the logic jumps back to the previous invalid value and uses this step size to determine a more accurate delay value. Reset Source: ctl_amod_g_rst_n
  [7:0] PHY_WDQLVL_DLY_STEP_3 — DQ target delay step size during write data leveling for slice 3. Reset Source: ctl_amod_g_rst_n
0x4DA4 emif_ctlcfg_DENALI_PHY_873
  [11:8] PHY_RDLVL_DLY_STEP_3 — DQS target delay step size during read leveling for slice 3. Reset Source: ctl_amod_g_rst_n
  [0] PHY_TOGGLE_PRE_SUPPORT_3 — Support the toggle read preamble for LPDDR4 for slice 3. Reset Source: ctl_amod_g_rst_n
0x4DA8 emif_ctlcfg_DENALI_PHY_874
  [9:0] PHY_RDLVL_MAX_EDGE_3 — The maximun rdlvl target delay search window for read eye training for slice 3. Reset Source: ctl_amod_g_rst_n
0x4DAC emif_ctlcfg_DENALI_PHY_875 reset 0x30000
  [17:16] PHY_DATA_DC_INIT_DISABLE_3 — Disable duty cycle adjust at initialization for slice 3. Reset Source: ctl_amod_g_rst_n
  [10:8] PHY_WRPATH_GATE_TIMING_3 — Write path clock gating timing for slice 3. it means additional clock number to write path clock gate Reset Source: ctl_amod_g_rst_n
  [1:0] PHY_WRPATH_GATE_DISABLE_3 — Write path clock gating disable for slice 3. [0]: disable pull in wrdata_en; [1]: disable write path clock gating, clock always on Reset Source: ctl_amod_g_rst_n
0x4DB0 emif_ctlcfg_DENALI_PHY_876
  [26:16] PHY_DATA_DC_DQ_INIT_SLV_DELAY_3 — Initial value of write DQ target delay for slice 3. Reset Source: ctl_amod_g_rst_n
  [9:0] PHY_DATA_DC_DQS_INIT_SLV_DELAY_3 — Initial value of write DQS target delay for slice 3. Reset Source: ctl_amod_g_rst_n
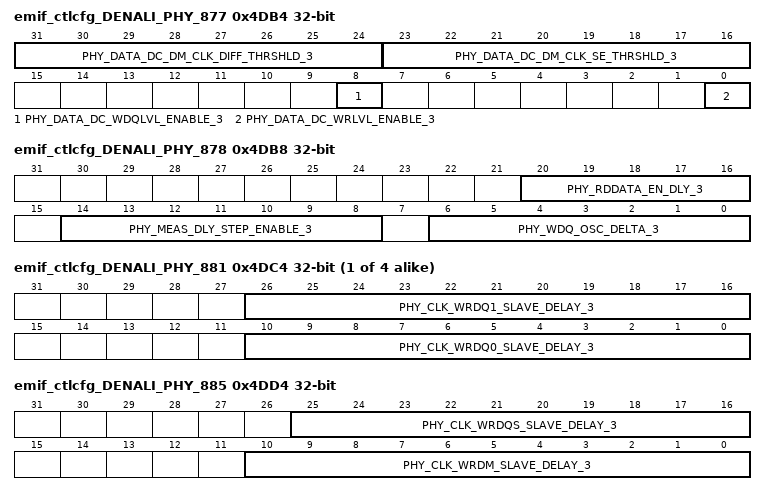
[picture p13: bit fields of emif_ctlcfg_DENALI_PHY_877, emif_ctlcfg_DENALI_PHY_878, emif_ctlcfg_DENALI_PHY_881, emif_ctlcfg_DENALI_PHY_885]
0x4DB4 emif_ctlcfg_DENALI_PHY_877
  [31:24] PHY_DATA_DC_DM_CLK_DIFF_THRSHLD_3 — Clock measurement cell threshold offset for differential signals for slice 3. Reset Source: ctl_amod_g_rst_n
  [23:16] PHY_DATA_DC_DM_CLK_SE_THRSHLD_3 — Clock measurement cell threshold offset for single ended signals for slice 3. Reset Source: ctl_amod_g_rst_n
  [8] PHY_DATA_DC_WDQLVL_ENABLE_3 — Enable duty cycle adjust during write DQ training for slice 3. Reset Source: ctl_amod_g_rst_n
  [0] PHY_DATA_DC_WRLVL_ENABLE_3 — Enable duty cycle adjust during write leveling for slice 3. Reset Source: ctl_amod_g_rst_n
0x4DB8 emif_ctlcfg_DENALI_PHY_878
  [20:16] PHY_RDDATA_EN_DLY_3 — Number of cycles that the dfi_rddata_en signal is early for slice 3. Reset Source: ctl_amod_g_rst_n
  [14:8] PHY_MEAS_DLY_STEP_ENABLE_3 — Data slice training step definition using phy_meas_dly_step_value for slice 3. Reset Source: ctl_amod_g_rst_n
  [6:0] PHY_WDQ_OSC_DELTA_3 — Target delay offset that applies to a 1 bit change of dfi_wdq_osc_code for slice 3. Reset Source: ctl_amod_g_rst_n
0x4DBC emif_ctlcfg_DENALI_PHY_879
  [31:0] PHY_DQ_DM_SWIZZLE0_3 — DQ/DM bit swizzling 0 for slice 3. Bits [3:0] inform the PHY which bit in {DM,DQ]} map to DQ0, Bits [7:4] inform the PHY which bit in {DM,DQ} map to DQ1, etc. Reset Source: ctl_amod_g_rst_n
0x4DC0 emif_ctlcfg_DENALI_PHY_880
  [3:0] PHY_DQ_DM_SWIZZLE1_3 — DQ/DM bit swizzling 1 for slice 3. Bits [3:0] inform the PHY which bit in {DM,DQ]} map to DM. Reset Source: ctl_amod_g_rst_n
{0x4000+4i} emif_ctlcfg_DENALI_PHY_{i} (i=881..884)
  [26:16] PHY_CLK_WRDQ{2i-1761}_SLAVE_DELAY_3 — Write clock target delay setting for DQ{2i-1761} for slice 3. Reset Source: ctl_amod_g_rst_n
  [10:0] PHY_CLK_WRDQ{2i-1762}_SLAVE_DELAY_3 — Write clock target delay setting for DQ{2i-1762} for slice 3. Reset Source: ctl_amod_g_rst_n
0x4DD4 emif_ctlcfg_DENALI_PHY_885
  [25:16] PHY_CLK_WRDQS_SLAVE_DELAY_3 — Write clock target delay setting for DQS for slice 3. Reset Source: ctl_amod_g_rst_n
  [10:0] PHY_CLK_WRDM_SLAVE_DELAY_3 — Write clock target delay setting for DM for slice 3. Reset Source: ctl_amod_g_rst_n
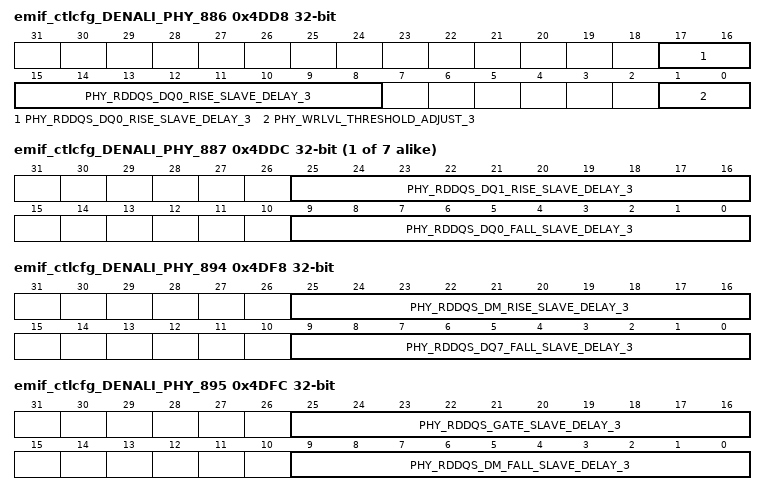
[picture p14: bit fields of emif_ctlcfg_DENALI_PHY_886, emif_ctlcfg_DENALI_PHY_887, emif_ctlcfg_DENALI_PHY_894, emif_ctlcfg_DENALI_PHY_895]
0x4DD8 emif_ctlcfg_DENALI_PHY_886
  [17:8] PHY_RDDQS_DQ0_RISE_SLAVE_DELAY_3 — Rising edge read DQS target delay setting for DQ0 for slice 3. Reset Source: ctl_amod_g_rst_n
  [1:0] PHY_WRLVL_THRESHOLD_ADJUST_3 — Write level threshold adjust value based on those thresholds for DQS for slice 3. Reset Source: ctl_amod_g_rst_n
{0x4000+4i} emif_ctlcfg_DENALI_PHY_{i} (i=887..893)
  [25:16] PHY_RDDQS_DQ{i-886}_RISE_SLAVE_DELAY_3 — Rising edge read DQS target delay setting for DQ{i-886} for slice 3. Reset Source: ctl_amod_g_rst_n
  [9:0] PHY_RDDQS_DQ{i-887}_FALL_SLAVE_DELAY_3 — Falling edge read DQS target delay setting for DQ{i-887} for slice 3. Reset Source: ctl_amod_g_rst_n
0x4DF8 emif_ctlcfg_DENALI_PHY_894
  [25:16] PHY_RDDQS_DM_RISE_SLAVE_DELAY_3 — Rising edge read DQS target delay setting for DM for slice 3. Reset Source: ctl_amod_g_rst_n
  [9:0] PHY_RDDQS_DQ7_FALL_SLAVE_DELAY_3 — Falling edge read DQS target delay setting for DQ7 for slice 3. Reset Source: ctl_amod_g_rst_n
0x4DFC emif_ctlcfg_DENALI_PHY_895
  [25:16] PHY_RDDQS_GATE_SLAVE_DELAY_3 — Read DQS target delay setting for slice 3. Reset Source: ctl_amod_g_rst_n
  [9:0] PHY_RDDQS_DM_FALL_SLAVE_DELAY_3 — Falling edge read DQS target delay setting for DM for slice 3. Reset Source: ctl_amod_g_rst_n
0x4E00 emif_ctlcfg_DENALI_PHY_896
  [25:16] PHY_WRLVL_DELAY_EARLY_THRESHOLD_3 — Write level delay threshold above which will be considered in previous cycle for slice 3. Reset Source: ctl_amod_g_rst_n
  [10:8] PHY_WRITE_PATH_LAT_ADD_3 — Number of cycles to delay the incoming dfi_wrdata_en/dfi_wrdata signals for slice 3. Reset Source: ctl_amod_g_rst_n
  [3:0] PHY_RDDQS_LATENCY_ADJUST_3 — Number of cycles to delay the incoming dfi_rddata_en for read DQS gate generation for slice 3. Reset Source: ctl_amod_g_rst_n
0x4E04 emif_ctlcfg_DENALI_PHY_897
  [16] PHY_WRLVL_EARLY_FORCE_ZERO_3 — Force the final write level delay value [that meets the early threshold] to 0 for slice 3. Reset Source: ctl_amod_g_rst_n
  [9:0] PHY_WRLVL_DELAY_PERIOD_THRESHOLD_3 — Write level delay threshold below which will add a cycle of write path latency for slice 3. Reset Source: ctl_amod_g_rst_n
0x4E08 emif_ctlcfg_DENALI_PHY_898
  [19:16] PHY_GTLVL_LAT_ADJ_START_3 — Initial read DQS gate cycle delay from dfi_rddata_en during gate training for slice 3. Reset Source: ctl_amod_g_rst_n
  [9:0] PHY_GTLVL_RDDQS_SLV_DLY_START_3 — Initial read DQS gate target delay setting during gate training for slice 3. Reset Source: ctl_amod_g_rst_n
0x4E0C emif_ctlcfg_DENALI_PHY_899
  [24] PHY_NTP_PASS_3 — Indicates if No-topology training found a passing result for slice 3. Reset Source: ctl_amod_g_rst_n
  [19:16] PHY_NTP_WRLAT_START_3 — Initial value for phy_write_path_lat_add for No-topology training and early threshold for slice 3. Reset Source: ctl_amod_g_rst_n
  [10:0] PHY_WDQLVL_DQDM_SLV_DLY_START_3 — Initial DQ/DM target delay setting during write data leveling for slice 3. Reset Source: ctl_amod_g_rst_n
0x4E10 emif_ctlcfg_DENALI_PHY_900
  [9:0] PHY_RDLVL_RDDQS_DQ_SLV_DLY_START_3 — Read leveling starting value for the DQS/DQ target delay settings for slice 3. Reset Source: ctl_amod_g_rst_n
0x4E14 emif_ctlcfg_DENALI_PHY_901 reset 0x20202020
  [31:24] PHY_DATA_DC_DQ2_CLK_ADJUST_3 — Adjust value of Duty Cycle Adjuster for slice 3. Reset Source: ctl_amod_g_rst_n
  [23:16] PHY_DATA_DC_DQ1_CLK_ADJUST_3 — Adjust value of Duty Cycle Adjuster for slice 3. Reset Source: ctl_amod_g_rst_n
  [15:8] PHY_DATA_DC_DQ0_CLK_ADJUST_3 — Adjust value of Duty Cycle Adjuster for slice 3. Reset Source: ctl_amod_g_rst_n
  [7:0] PHY_DATA_DC_DQS_CLK_ADJUST_3 — Adjust value of Duty Cycle Adjuster for slice 3. Reset Source: ctl_amod_g_rst_n
0x4E18 emif_ctlcfg_DENALI_PHY_902 reset 0x20202020
  [8n-17:8n-24] PHY_DATA_DC_DQ{n}_CLK_ADJUST_3 (n=3..6) — Adjust value of Duty Cycle Adjuster for slice 3. Reset Source: ctl_amod_g_rst_n
0x4E1C emif_ctlcfg_DENALI_PHY_903 reset 0x2020
  [31:16] PHY_DSLICE_PAD_BOOSTPN_SETTING_3 — Setting for boost P/N of pad for slice 3. Reset Source: ctl_amod_g_rst_n
  [15:8] PHY_DATA_DC_DM_CLK_ADJUST_3 — Adjust value of Duty Cycle Adjuster for slice 3. Reset Source: ctl_amod_g_rst_n
  [7:0] PHY_DATA_DC_DQ7_CLK_ADJUST_3 — Adjust value of Duty Cycle Adjuster for slice 3. Reset Source: ctl_amod_g_rst_n
0x4E20 emif_ctlcfg_DENALI_PHY_904
  [17:16] PHY_DQS_FFE_3 — TX_FFE setting for DQS pad for slice 3. Reset Source: ctl_amod_g_rst_n
  [9:8] PHY_DQ_FFE_3 — TX_FFE setting for DQ/DM pad for slice 3. Reset Source: ctl_amod_g_rst_n
  [5:0] PHY_DSLICE_PAD_RX_CTLE_SETTING_3 — Setting for RX ctle P/N of pad for slice 3. Reset Source: ctl_amod_g_rst_n
0x5000 emif_ctlcfg_DENALI_PHY_1024 access per field
  [26:24] SC_PHY_ADR_MANUAL_CLEAR_0 wo — Manual reset/clear of internal logic for address slice 0. Bit [0] is reset of master delay min/max lock values. Bit [1] is manual reset of master delay unlock counter. Bit [2] clears the loopback error/results registers. Set each bit to 1 to reset. WRITE-ONLY Reset Source: ctl_amod_g_rst_n
  [16] PHY_ADR_CLK_BYPASS_OVERRIDE_0 rw — Bypass mode override setting for address slice 0. Set to 1 to enable. Reset Source: ctl_amod_g_rst_n
  [10:0] PHY_ADR_CLK_WR_BYPASS_SLAVE_DELAY_0 rw — Command/Address clock bypass mode target delay setting for address slice 0. Reset Source: ctl_amod_g_rst_n
0x5004 emif_ctlcfg_DENALI_PHY_1025 ro reset 0x1000
  [31:0] PHY_ADR_LPBK_RESULT_OBS_0 — Observation register containing loopback status/results for address slice 0. READ-ONLY Reset Source: ctl_amod_g_rst_n
0x5008 emif_ctlcfg_DENALI_PHY_1026 access per field
  [27:24] PHY_ADR_MASTER_DLY_LOCK_OBS_SELECT_0 rw — Select value to map the internal master delay observation registers to the accessible master delay observation register for address slice 0. Reset Source: ctl_amod_g_rst_n
  [23:16] PHY_ADR_MEAS_DLY_STEP_VALUE_0 ro — Contains the fraction of a cycle in 1 delay element numerator with demominator of 512, for address slice 0. READ-ONLY Reset Source: ctl_amod_g_rst_n
  [15:0] PHY_ADR_LPBK_ERROR_COUNT_OBS_0 ro — Observation register containing total number of loopback error data for address slice 0. READ-ONLY Reset Source: ctl_amod_g_rst_n
0x500C emif_ctlcfg_DENALI_PHY_1027 ro
  [31:24] PHY_ADR_ADDER_SLV_DLY_ENC_OBS_0 — Observation register containing addr target delay for address slice 0. READ-ONLY Reset Source: ctl_amod_g_rst_n
  [22:16] PHY_ADR_BASE_SLV_DLY_ENC_OBS_0 — Observation register containing base target delay for address slice 0. READ-ONLY Reset Source: ctl_amod_g_rst_n
  [10:0] PHY_ADR_MASTER_DLY_LOCK_OBS_0 — Observation register containing master delay results for address slice 0. READ-ONLY Reset Source: ctl_amod_g_rst_n
0x5010 emif_ctlcfg_DENALI_PHY_1028 access per field
  [24] PHY_ADR_TSEL_ENABLE_0 rw — Enables tsel_en for address slice 0. Reset Source: ctl_amod_g_rst_n
  [16] SC_PHY_ADR_SNAP_OBS_REGS_0 wo — Initiates a snapshot of the internal observation registers for address slice 0. Set to 1 to trigger. WRITE-ONLY Reset Source: ctl_amod_g_rst_n
  [10:8] PHY_ADR_SLV_DLY_ENC_OBS_SELECT_0 rw — Select value to map the addr bits delay observation registers to the accessible delay observation register for address slice 0. Reset Source: ctl_amod_g_rst_n
  [2:0] PHY_ADR_SLAVE_LOOP_CNT_UPDATE_0 rw — Reserved for address slice 0. Reset Source: ctl_amod_g_rst_n
0x5014 emif_ctlcfg_DENALI_PHY_1029 reset 0x100
  [24] PHY_ADR_PWR_RDC_DISABLE_0 — Power reduction disable for address slice 0. Reset Source: ctl_amod_g_rst_n
  [20:16] PHY_ADR_PRBS_PATTERN_MASK_0 — PRBS7 mask signal for address slice 0. Reset Source: ctl_amod_g_rst_n
  [14:8] PHY_ADR_PRBS_PATTERN_START_0 — PRBS7 start pattern for address slice 0. Reset Source: ctl_amod_g_rst_n
  [6:0] PHY_ADR_LPBK_CONTROL_0 — Loopback control bits for address slice 0. Reset Source: ctl_amod_g_rst_n
0x5018 emif_ctlcfg_DENALI_PHY_1030 access per field
  [24] PHY_ADR_IE_MODE_0 rw — Input enable control for address slice 0. Reset Source: ctl_amod_g_rst_n
  [18:16] PHY_ADR_WRADDR_SHIFT_OBS_0 ro — Observation register containing automatic half cycle and cycle shift values for address slice 0. READ-ONLY Reset Source: ctl_amod_g_rst_n
  [9:8] PHY_ADR_TYPE_0 rw — DRAM type for address slice 0. Reset Source: ctl_amod_g_rst_n
  [0] PHY_ADR_SLV_DLY_CTRL_GATE_DISABLE_0 rw — Power reduction slv_dly_control block gate disable for address slice 0. Reset Source: ctl_amod_g_rst_n
0x501C emif_ctlcfg_DENALI_PHY_1031
  [26:0] PHY_ADR_DDL_MODE_0 — DDL mode for address slice 0. Reset Source: ctl_amod_g_rst_n
0x5020 emif_ctlcfg_DENALI_PHY_1032
  [5:0] PHY_ADR_DDL_MASK_0 — DDL mask for address slice 0. Reset Source: ctl_amod_g_rst_n
0x5024 emif_ctlcfg_DENALI_PHY_1033 ro
  [31:0] PHY_ADR_DDL_TEST_OBS_0 — Observation register containing DDL test bits for address slice 0. READ-ONLY Reset Source: ctl_amod_g_rst_n
0x5028 emif_ctlcfg_DENALI_PHY_1034 ro
  [31:0] PHY_ADR_DDL_TEST_MSTR_DLY_OBS_0 — Observation register containing master DDL bits for address slice 0. READ-ONLY Reset Source: ctl_amod_g_rst_n
0x502C emif_ctlcfg_DENALI_PHY_1035
  [26:16] PHY_ADR_CALVL_COARSE_DLY_0 — Coarse CA training DDL increment value for address slice 0. Reset Source: ctl_amod_g_rst_n
  [10:0] PHY_ADR_CALVL_START_0 — CA training DDL start value for address slice 0. Reset Source: ctl_amod_g_rst_n
0x5030 emif_ctlcfg_DENALI_PHY_1036
  [10:0] PHY_ADR_CALVL_QTR_0 — CA training DDL quarter cycle delay value for address slice 0. Reset Source: ctl_amod_g_rst_n
0x5034 emif_ctlcfg_DENALI_PHY_1037
  [23:0] PHY_ADR_CALVL_SWIZZLE0_0 — CA training RD DQ bit swizzle map 0 for address slice 0. Reset Source: ctl_amod_g_rst_n
0x5038 emif_ctlcfg_DENALI_PHY_1038
  [25:24] PHY_ADR_CALVL_RANK_CTRL_0 — CA training rank aggregation control bits for address slice 0. Reset Source: ctl_amod_g_rst_n
  [23:0] PHY_ADR_CALVL_SWIZZLE1_0 — CA training RD DQ bit swizzle map 1 for address slice 0. Reset Source: ctl_amod_g_rst_n
0x503C emif_ctlcfg_DENALI_PHY_1039
  [24:16] PHY_ADR_CALVL_PERIODIC_START_OFFSET_0 — Relative offset to start periodic CALVL from previous result Reset Source: ctl_amod_g_rst_n
  [11:8] PHY_ADR_CALVL_RESP_WAIT_CNT_0 — Number of samples to wait before sampling response during CA training for address slice 0. Reset Source: ctl_amod_g_rst_n
  [1:0] PHY_ADR_CALVL_NUM_PATTERNS_0 — Number of patterns to use during CA training for address slice 0. Reset Source: ctl_amod_g_rst_n
